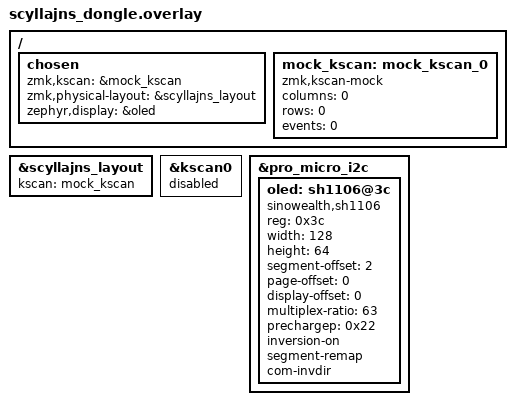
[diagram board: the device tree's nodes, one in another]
#include "scyllajns.dtsi"

/ {
    chosen {
        zmk,kscan = &mock_kscan;
        zmk,physical-layout = &scyllajns_layout;
        zephyr,display = &oled;
    };

    mock_kscan: mock_kscan_0 {
        compatible = "zmk,kscan-mock";
        columns = <0>;
        rows = <0>;
        events = <0>;
    };
};

/* Vincula o layout ao kscan mock */
&scyllajns_layout {
    kscan = <&mock_kscan>;
};

/* Desativa o kscan real */
&kscan0 {
    status = "disabled";
};

&pro_micro_i2c {
    status = "okay";

    oled: sh1106@3c {
        compatible = "sinowealth,sh1106";
        reg = <0x3c>;
        width = <128>;
        height = <64>;
        segment-offset = <2>;
        page-offset = <0>;
        display-offset = <0>;
        multiplex-ratio = <63>;
        prechargep = <0x22>;
        inversion-on;
        segment-remap;
        com-invdir;
    };
};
